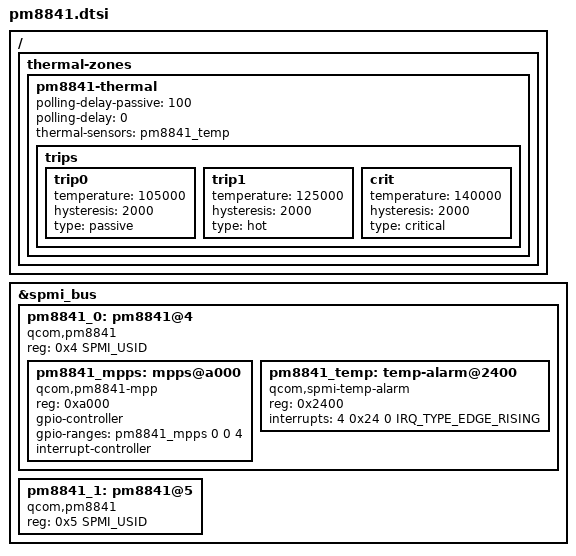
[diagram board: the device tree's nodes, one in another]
// SPDX-License-Identifier: GPL-2.0
#include <dt-bindings/interrupt-controller/irq.h>
#include <dt-bindings/spmi/spmi.h>


/ {
	thermal-zones {
		pm8841-thermal {
			polling-delay-passive = <100>;
			polling-delay = <0>;
			thermal-sensors = <&pm8841_temp>;

			trips {
				trip0 {
					temperature = <105000>;
					hysteresis = <2000>;
					type = "passive";
				};

				trip1 {
					temperature = <125000>;
					hysteresis = <2000>;
					type = "hot";
				};

				crit {
					temperature = <140000>;
					hysteresis = <2000>;
					type = "critical";
				};
			};
		};
	};
};

&spmi_bus {

	pm8841_0: pm8841@4 {
		compatible = "qcom,pm8841", "qcom,spmi-pmic";
		reg = <0x4 SPMI_USID>;
		#address-cells = <1>;
		#size-cells = <0>;

		pm8841_mpps: mpps@a000 {
			compatible = "qcom,pm8841-mpp", "qcom,spmi-mpp";
			reg = <0xa000>;
			gpio-controller;
			#gpio-cells = <2>;
			gpio-ranges = <&pm8841_mpps 0 0 4>;
			interrupt-controller;
			#interrupt-cells = <2>;
		};

		pm8841_temp: temp-alarm@2400 {
			compatible = "qcom,spmi-temp-alarm";
			reg = <0x2400>;
			interrupts = <4 0x24 0 IRQ_TYPE_EDGE_RISING>;
			#thermal-sensor-cells = <0>;
		};
	};

	pm8841_1: pm8841@5 {
		compatible = "qcom,pm8841", "qcom,spmi-pmic";
		reg = <0x5 SPMI_USID>;
		#address-cells = <1>;
		#size-cells = <0>;
	};
};
